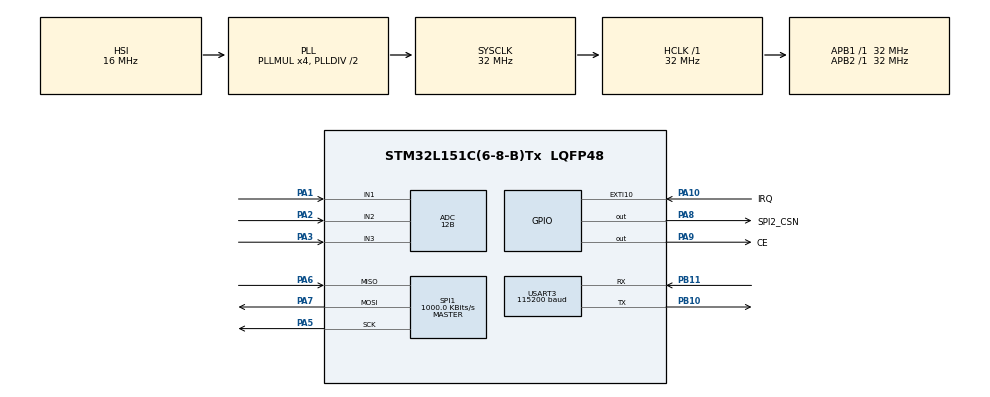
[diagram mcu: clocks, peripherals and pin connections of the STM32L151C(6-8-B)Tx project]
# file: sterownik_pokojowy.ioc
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ADC.Channel-0\#ChannelRegularConversion=ADC_CHANNEL_1
ADC.Channel-4\#ChannelRegularConversion=ADC_CHANNEL_2
ADC.Channel-5\#ChannelRegularConversion=ADC_CHANNEL_3
ADC.Channel-IN1=ADC_CHANNEL_1
ADC.Channel-IN2=ADC_CHANNEL_2
ADC.Channel-IN3=ADC_CHANNEL_3
ADC.ClockPrescaler=ADC_CLOCK_ASYNC_DIV4
ADC.ContinuousConvMode=ENABLE
ADC.DMAContinuousRequests=ENABLE
ADC.DataAlign=ADC_DATAALIGN_RIGHT
ADC.DiscontinuousConvMode=DISABLE
ADC.EOCSelection=ADC_EOC_SINGLE_CONV
ADC.EnableAnalogWatchDog=false
ADC.ExternalTrigConv=ADC_SOFTWARE_START
ADC.ExternalTrigConvEdge=ADC_EXTERNALTRIGCONVEDGE_NONE
ADC.InjNumberOfConversion=0
ADC.LowPowerAutoPowerOff=ADC_AUTOPOWEROFF_DISABLE
ADC.LowPowerAutoWait=ADC_AUTOWAIT_DISABLE
ADC.NbrOfConversion=3
ADC.Rank-0\#ChannelRegularConversion=1
ADC.Rank-4\#ChannelRegularConversion=2
ADC.Rank-5\#ChannelRegularConversion=3
ADC.Resolution=ADC_RESOLUTION_12B
ADC.SamplingTime-0\#ChannelRegularConversion=ADC_SAMPLETIME_384CYCLES
ADC.SamplingTime-4\#ChannelRegularConversion=ADC_SAMPLETIME_384CYCLES
ADC.SamplingTime-5\#ChannelRegularConversion=ADC_SAMPLETIME_384CYCLES
ADC.ScanConvMode=ADC_SCAN_ENABLE
Dma.ADC.2.Direction=DMA_PERIPH_TO_MEMORY
Dma.ADC.2.Instance=DMA1_Channel1
Dma.ADC.2.MemDataAlignment=DMA_MDATAALIGN_HALFWORD
Dma.ADC.2.MemInc=DMA_MINC_ENABLE
Dma.ADC.2.Mode=DMA_CIRCULAR
Dma.ADC.2.PeriphDataAlignment=DMA_PDATAALIGN_HALFWORD
Dma.ADC.2.PeriphInc=DMA_PINC_DISABLE
Dma.ADC.2.Priority=DMA_PRIORITY_VERY_HIGH
Dma.Request0=USART3_RX
Dma.Request1=USART3_TX
Dma.Request2=ADC
Dma.USART3_RX.0.Direction=DMA_PERIPH_TO_MEMORY
Dma.USART3_RX.0.Instance=DMA1_Channel3
Dma.USART3_RX.0.MemDataAlignment=DMA_MDATAALIGN_BYTE
Dma.USART3_RX.0.MemInc=DMA_MINC_ENABLE
Dma.USART3_RX.0.Mode=DMA_NORMAL
Dma.USART3_RX.0.PeriphDataAlignment=DMA_PDATAALIGN_BYTE
Dma.USART3_RX.0.PeriphInc=DMA_PINC_DISABLE
Dma.USART3_RX.0.Priority=DMA_PRIORITY_MEDIUM
Dma.USART3_TX.1.Direction=DMA_MEMORY_TO_PERIPH
Dma.USART3_TX.1.Instance=DMA1_Channel2
Dma.USART3_TX.1.MemDataAlignment=DMA_MDATAALIGN_BYTE
Dma.USART3_TX.1.MemInc=DMA_MINC_ENABLE
Dma.USART3_TX.1.Mode=DMA_NORMAL
Dma.USART3_TX.1.PeriphDataAlignment=DMA_PDATAALIGN_BYTE
Dma.USART3_TX.1.PeriphInc=DMA_PINC_DISABLE
Dma.USART3_TX.1.Priority=DMA_PRIORITY_MEDIUM
Mcu.Family=STM32L1
Mcu.Name=STM32L151C(6-8-B)Tx
Mcu.Package=LQFP48
NVIC.ADC1_IRQn=true\:0\:0\:false\:false\:true\:true\:true\:true
NVIC.DMA1_Channel1_IRQn=true\:0\:0\:false\:false\:true\:false\:true\:true
NVIC.DMA1_Channel2_IRQn=true\:0\:0\:false\:false\:true\:false\:true\:true
NVIC.DMA1_Channel3_IRQn=true\:0\:0\:false\:false\:true\:false\:true\:true
NVIC.EXTI15_10_IRQn=true\:0\:0\:false\:false\:true\:true\:true\:true
NVIC.PriorityGroup=NVIC_PRIORITYGROUP_4
NVIC.SPI1_IRQn=true\:0\:0\:false\:false\:true\:true\:true\:true
NVIC.TIM11_IRQn=true\:0\:0\:false\:false\:true\:true\:true\:true
NVIC.USART3_IRQn=true\:0\:0\:false\:false\:true\:true\:true\:true
PA1.Mode=IN1
PA1.Signal=ADC_IN1
PA10.GPIO_Label=IRQ
PA10.GPIO_ModeDefaultEXTI=GPIO_MODE_IT_FALLING
PA10.Signal=GPXTI10
PA2.Mode=IN2
PA2.Signal=ADC_IN2
PA3.Mode=IN3
PA3.Signal=ADC_IN3
PA5.Mode=Full_Duplex_Master
PA5.Signal=SPI1_SCK
PA6.Mode=Full_Duplex_Master
PA6.Signal=SPI1_MISO
PA7.Mode=Full_Duplex_Master
PA7.Signal=SPI1_MOSI
PA8.GPIO_Label=SPI2_CSN
PA8.GPIO_Speed=GPIO_SPEED_FREQ_VERY_HIGH
PA8.PinState=GPIO_PIN_SET
PA8.Signal=GPIO_Output
PA9.GPIO_Label=CE
PA9.GPIO_Speed=GPIO_SPEED_FREQ_VERY_HIGH
PA9.Signal=GPIO_Output
PB10.Mode=Asynchronous
PB10.Signal=USART3_TX
PB11.Mode=Asynchronous
PB11.Signal=USART3_RX
ProjectManager.HeapSize=0x200
ProjectManager.StackSize=0x400
ProjectManager.TargetToolchain=STM32CubeIDE
RCC.48MHZClocksFreq_Value=32000000
RCC.AHBFreq_Value=32000000
RCC.APB1Freq_Value=32000000
RCC.APB1TimFreq_Value=32000000
RCC.APB2Freq_Value=32000000
RCC.APB2TimFreq_Value=32000000
RCC.FLatency=FLASH_LATENCY_1
RCC.HCLKFreq_Value=32000000
RCC.HSE_VALUE=24000000
RCC.HSI_VALUE=16000000
RCC.LSE_VALUE=32768
RCC.MSI_VALUE=2097000
RCC.PLLMUL=RCC_PLL_MUL4
RCC.SYSCLKFreq_VALUE=32000000
RCC.SYSCLKSource=RCC_SYSCLKSOURCE_PLLCLK
RCC.VCOOutputFreq_Value=64000000
SPI1.BaudRatePrescaler=SPI_BAUDRATEPRESCALER_32
SPI1.CLKPhase=SPI_PHASE_1EDGE
SPI1.CLKPolarity=SPI_POLARITY_LOW
SPI1.CRCCalculation=SPI_CRCCALCULATION_DISABLE
SPI1.CalculateBaudRate=1000.0 KBits/s
SPI1.DataSize=SPI_DATASIZE_8BIT
SPI1.Direction=SPI_DIRECTION_2LINES
SPI1.Mode=SPI_MODE_MASTER
SPI1.NSS=SPI_NSS_SOFT
SPI1.VirtualType=VM_MASTER
TIM11.AutoReloadPreload=TIM_AUTORELOAD_PRELOAD_DISABLE
TIM11.ClockDivision=TIM_CLOCKDIVISION_DIV1
TIM11.CounterMode=TIM_COUNTERMODE_UP
TIM11.Period=64515
TIM11.Prescaler=991
USART3.BaudRate=115200
USART3.Mode=MODE_TX_RX
USART3.OverSampling=UART_OVERSAMPLING_8
USART3.Parity=PARITY_NONE
USART3.StopBits=STOPBITS_1
USART3.VirtualMode=VM_ASYNC
USART3.WordLength=WORDLENGTH_8B
VP_TIM11_VS_ClockSourceINT.Mode=Internal
board=custom

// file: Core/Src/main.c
/* USER CODE BEGIN Header */
/**
  ******************************************************************************
  * @file           : main.c
  * @brief          : Main program body
  ******************************************************************************
  * @attention
  *
  * Copyright (c) 2025 STMicroelectronics.
  * All rights reserved.
  *
  * This software is licensed under terms that can be found in the LICENSE file
  * in the root directory of this software component.
  * If no LICENSE file comes with this software, it is provided AS-IS.
  *
  ******************************************************************************
  */
/* USER CODE END Header */
#include "main.h"
#include "adc.h"
#include "dma.h"
#include "spi.h"
#include "tim.h"
#include "usart.h"
#include "gpio.h"

/* USER CODE BEGIN Includes */
#include "init.h"
#include "cycle.h"
#include "nrf24l01p.h"
/* USER CODE END Includes */

void SystemClock_Config(void);

int main(void)
{

  /* MCU Configuration--------------------------------------------------------*/

  /* Reset of all peripherals, Initializes the Flash interface and the Systick. */
  HAL_Init();

  /* Configure the system clock */
  SystemClock_Config();

  /* Initialize all configured peripherals */
  MX_GPIO_Init();
  MX_DMA_Init();
  MX_SPI1_Init();
  MX_USART3_UART_Init();
  MX_ADC_Init();
  MX_TIM11_Init();
  /* USER CODE BEGIN 2 */

  HAL_Delay(500);
  init();

  /* USER CODE END 2 */

  /* Infinite loop */
  /* USER CODE BEGIN WHILE */
  while (1)
  {

	  cycle();

    /* USER CODE END WHILE */

  }
}

void SystemClock_Config(void)
{
  RCC_OscInitTypeDef RCC_OscInitStruct = {0};
  RCC_ClkInitTypeDef RCC_ClkInitStruct = {0};

  /** Configure the main internal regulator output voltage
  */
  __HAL_PWR_VOLTAGESCALING_CONFIG(PWR_REGULATOR_VOLTAGE_SCALE1);

  /** Initializes the RCC Oscillators according to the specified parameters
  * in the RCC_OscInitTypeDef structure.
  */
  RCC_OscInitStruct.OscillatorType = RCC_OSCILLATORTYPE_HSI;
  RCC_OscInitStruct.HSIState = RCC_HSI_ON;
  RCC_OscInitStruct.HSICalibrationValue = RCC_HSICALIBRATION_DEFAULT;
  RCC_OscInitStruct.PLL.PLLState = RCC_PLL_ON;
  RCC_OscInitStruct.PLL.PLLSource = RCC_PLLSOURCE_HSI;
  RCC_OscInitStruct.PLL.PLLMUL = RCC_PLL_MUL4;
  RCC_OscInitStruct.PLL.PLLDIV = RCC_PLL_DIV2;
  if (HAL_RCC_OscConfig(&RCC_OscInitStruct) != HAL_OK)
  {
    Error_Handler();
  }

  /** Initializes the CPU, AHB and APB buses clocks
  */
  RCC_ClkInitStruct.ClockType = RCC_CLOCKTYPE_HCLK|RCC_CLOCKTYPE_SYSCLK
                              |RCC_CLOCKTYPE_PCLK1|RCC_CLOCKTYPE_PCLK2;
  RCC_ClkInitStruct.SYSCLKSource = RCC_SYSCLKSOURCE_PLLCLK;
  RCC_ClkInitStruct.AHBCLKDivider = RCC_SYSCLK_DIV1;
  RCC_ClkInitStruct.APB1CLKDivider = RCC_HCLK_DIV1;
  RCC_ClkInitStruct.APB2CLKDivider = RCC_HCLK_DIV1;

  if (HAL_RCC_ClockConfig(&RCC_ClkInitStruct, FLASH_LATENCY_1) != HAL_OK)
  {
    Error_Handler();
  }
}

void Error_Handler(void)
{
  __disable_irq();
  while (1)
  {
  }
}
